# R7FA4E2B9 register map
Vendor: Renesas Electronics Corporation; Series: RA4; File version: 1.30.00
CPU: CM33 r0p4, little endian, MPU, FPU, VTOR, 4 interrupt priority bits, 96 interrupts
Registers are 32-bit, read-write, reset 0x0 unless marked. A register's access mark holds for its fields unless they carry their own. Offsets are from the block's base; [hi:lo] are bit positions.

## CEC — Consumer Electronics Control
Base 0x400AC000
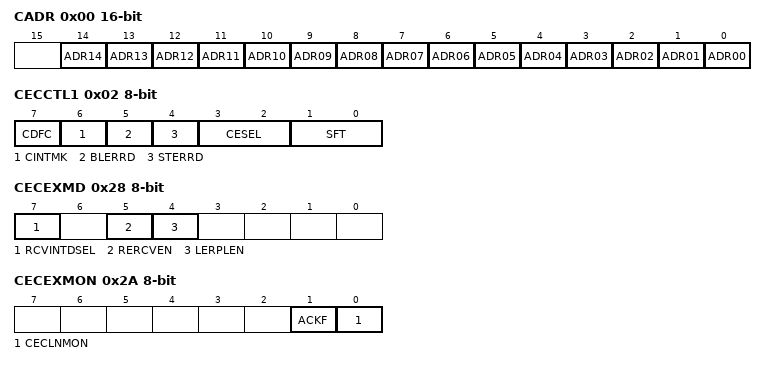
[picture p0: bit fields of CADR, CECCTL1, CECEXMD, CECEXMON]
0x00 CADR 16-bit — CEC Local Address Setting Register
  [14] ADR14 — Local Address Setting at Address 14 (specific use)
  [13] ADR13 — Local Address Setting at Address 13 (reserved)
  [12] ADR12 — Local Address Setting at Address 12 (reserved)
  [11] ADR11 — Local Address Setting at Address 11 (playback device 3)
  [10] ADR10 — Local Address Setting at Address 10 (tuner 4)
  [9] ADR09 — Local Address Setting at Address 9 (recording device 3)
  [8] ADR08 — Local Address Setting at Address 8 (playback device 2)
  [7] ADR07 — Local Address Setting at Address 7 (tuner 3)
  [6] ADR06 — Local Address Setting at Address 6 (tuner 2)
  [5] ADR05 — Local Address Setting at Address 5 (audio system)
  [4] ADR04 — Local Address Setting at Address 4 (playback device 1)
  [3] ADR03 — Local Address Setting at Address 3 (tuner 1)
  [2] ADR02 — Local Address Setting at Address 2 (recording device 2)
  [1] ADR01 — Local Address Setting at Address 1 (recording device 1)
  [0] ADR00 — Local Address at Address 0 (TV)
0x02 CECCTL1 8-bit — CEC Control Register 1
  [7] CDFC — Digital Filter Select
  [6] CINTMK — CEC Data Interrupt (INTDA) Generation Select
  [5] BLERRD — Bus Lock Detection Select
  [4] STERRD — Start Bit Error Detection Select
  [3:2] CESEL — Communication Complete Interrupt (INTCE) Generation Timing Select
  [1:0] SFT — Signal,Free Time Data Bit Width Select
0x04 STATB 16-bit — CEC Transmission Start Bit Width Setting Register
  [8:0] STATB — CEC Transmission Start Bit Width Setting
0x06 STATL 16-bit — CEC Transmission Start Bit Low Width Setting Register
  [8:0] STATL — CEC Transmission Start Bit Low Width Setting
0x08 LGC0L 16-bit — CEC Transmission Logical 0 Low Width Setting Register
  [8:0] LGC0L — CEC Transmission Logical 0 Low Width Setting
0x0A LGC1L 16-bit — CEC Transmission Logical 1 Low Width Setting Register
  [8:0] LGC1L — CEC Transmission Logical 1 Low Width Setting
0x0C DATB 16-bit — CEC Transmission Data Bit Width Setting Register
  [8:0] DATB — CEC Transmission Data Bit Width Setting
0x0E NOMT 16-bit — CEC Reception Data Sampling Time Setting Register
  [8:0] NOMT — CEC Reception Data Sampling Time Setting,
0x10 STATLL 16-bit — CEC Reception Start Bit Minimum Low Width Setting Register
  [8:0] STATLL — CEC Reception Start Bit Minimum Low Width Setting
0x12 STATLH 16-bit — CEC Reception Start Bit Maximum Low Width Setting Register
  [8:0] STATLH — CEC Reception Start Bit Maximum Bit Width Setting
0x14 STATBL 16-bit — CEC Reception Start Bit Minimum Bit Width Setting Register
  [8:0] STATBL — CEC Reception Start Bit Minimum Bit Width Setting
0x16 STATBH 16-bit — CEC Reception Start Bit Maximum Bit Width Setting Register
  [8:0] STATBH — CEC Reception Start Bit Maximum Bit Width Setting
0x18 LGC0LL 16-bit — CEC Reception Logical 0 Minimum Low Width Setting Register
  [8:0] LGC0LL — CEC Reception Logical 0 Minimum Low Width Setting
0x1A LGC0LH 16-bit — CEC Reception Logical 0 Maximum Low Width Setting Register
  [8:0] LGC0LH — CEC Reception Logical 0 Minimum Low Width Setting
0x1C LGC1LL 16-bit — CEC Reception Logical 1 Minimum Low Width Setting Register
  [8:0] LGC1LL — CEC Reception Logical 1 Minimum Low Width Setting
0x1E LGC1LH 16-bit — CEC Reception Logical 1 Maximum Low Width Setting Register
  [8:0] LGC1LH — CEC Reception Logical 1 Maximum Low Width Setting
0x20 DATBL 16-bit — CEC Reception Data Bit Minimum Bit Width Setting Register
  [8:0] DATBL — CEC Reception Data Bit Minimum Bit Width Setting
0x22 DATBH 16-bit — CEC Reception Data Bit Maximum Bit Width Setting Register
  [8:0] DATBH — CEC Reception Data Bit Maximum Bit Width Setting
0x24 NOMP 16-bit — CEC Data Bit Reference Width Setting Register
  [8:0] NOMP — CEC Data Bit Reference Width Setting
0x28 CECEXMD 8-bit — CEC Extension Mode Register
  [7] RCVINTDSEL — INTDA Reception Interrupt Timing Change
  [5] RERCVEN — Start Detection Reception Restart Enable
  [4] LERPLEN — Pulse Output Function Enable by Long Bit Width Error
0x2A CECEXMON 8-bit (reset mask 0xFE) — CEC Extension Monitor Register
  [1] ACKF ro — ACK Flag
  [0] CECLNMON ro — CEC Line Monitor
0x40 CTXD 8-bit — CEC Transmission Buffer Register
0x41 CRXD 8-bit — CEC Reception Buffer Register
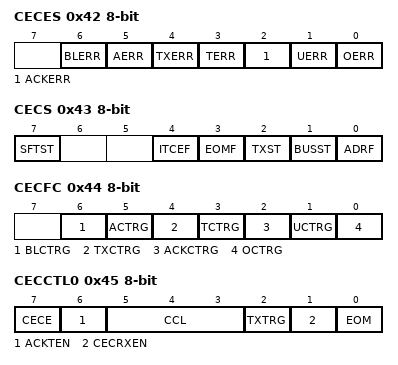
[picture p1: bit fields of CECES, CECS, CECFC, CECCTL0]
0x42 CECES 8-bit — CEC Communication Error Status Register
  [6] BLERR ro — Bus Lock Error Detection Flag
  [5] AERR ro — Arbitration Loss Detection Flag
  [4] TXERR ro — Transmission Error Detection Flag
  [3] TERR ro — Timing Error Detection Flag
  [2] ACKERR ro — ACK Error Detection Flag
  [1] UERR ro — Underrun Error Detection Flag
  [0] OERR ro — Overrun Error Detection Flag
0x43 CECS 8-bit — CEC Communication Status Register
  [7] SFTST ro — Signal,Free Time Rewrite Disable Report Flag
  [4] ITCEF ro — INTCE Generation Source Flag
  [3] EOMF ro — EOM Flag
  [2] TXST ro — Transmission Status Flag
  [1] BUSST ro — Bus Busy Detection Flag
  [0] ADRF ro — Address Match Detection Flag
0x44 CECFC 8-bit — CEC Communication Error Flag Clear Trigger Register
  [6] BLCTRG wo — Bus Lock Error Detection Flag Clear Trigger
  [5] ACTRG wo — Arbitration Loss Detection Flag Clear Trigger
  [4] TXCTRG wo — Transmission Error Detection Flag Clear Trigger
  [3] TCTRG wo — Timing Error Detection Flag Clear Trigger
  [2] ACKCTRG wo — ACK Error Detection Flag Clear Trigger
  [1] UCTRG wo — Underrun Error Detection Flag Clear Trigger
  [0] OCTRG wo — Overrun Error Detection Flag Clear Trigger
0x45 CECCTL0 8-bit — CEC Control Register 0
  [7] CECE — CEC Operation Enable Flag
  [6] ACKTEN — ACK Bit Timing Error (Bit Width) Check Enable
  [5:3] CCL — CEC Clock Select
  [2] TXTRG wo — Transmission Start Trigger
  [1] CECRXEN — Reception Enable Control
  [0] EOM — EOM Setting
